# S6E2GMxJ register map
Vendor: Spansion; File version: 2.0
CPU: CM4 r0p1, little endian, MPU, FPU, 4 interrupt priority bits
Registers are 32-bit, read-write, reset 0x0 unless marked. A register's access mark holds for its fields unless they carry their own. Offsets are from the block's base; [hi:lo] are bit positions; {n}, {i} and the like mark numbered series.

## ADC0 — ADC0 Registers
Base 0x40027000
Same registers: ADC1 0x40027100, ADC2 0x40027200
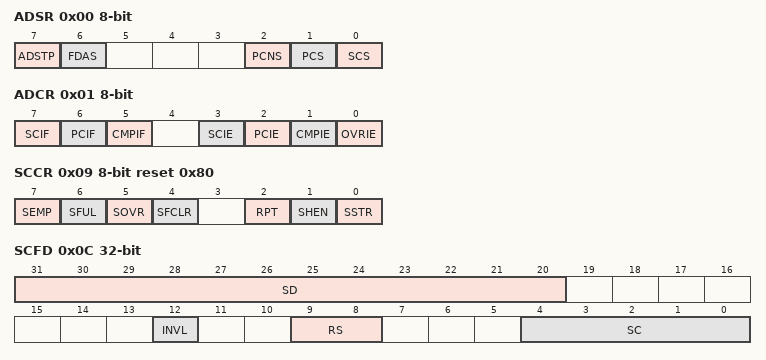
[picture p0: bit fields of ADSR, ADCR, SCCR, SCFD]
0x00 ADSR 8-bit — A/D Status Register
  [7] ADSTP — A/D conversion forced stop bit
  [6] FDAS — FIFO data placement selection bit
  [2] PCNS ro — Priority conversion pending flag
  [1] PCS ro — Priority conversion status flag
  [0] SCS ro — Scan conversion status flag
0x01 ADCR 8-bit — A/D Control Register
  [7] SCIF — Scan conversion interrupt request bit
  [6] PCIF — Priority conversion interrupt request bit
  [5] CMPIF — Conversion result comparison interrupt request bit
  [3] SCIE — Scan conversion interrupt enable bit
  [2] PCIE — Priority conversion interrupt enable bit
  [1] CMPIE — Conversion result comparison interrupt enable bit
  [0] OVRIE — FIFO overrun interrupt enable bit
0x08 SFNS 8-bit — Scan Conversion FIFO Stage Count Setup Register
  [3:0] SFS — Scan conversion FIFO stage count setting bit
0x09 SCCR 8-bit reset 0x80 — Scan Conversion Control Register
  [7] SEMP ro — Scan conversion FIFO empty bit
  [6] SFUL ro — Scan conversion FIFO full bit
  [5] SOVR — Scan conversion overrun flag
  [4] SFCLR — Scan conversion FIFO clear bit
  [2] RPT — Scan conversion repeat bit
  [1] SHEN — Scan conversion timer start enable bit
  [0] SSTR — Scan conversion start bit
0x0C SCFD ro — Scan Conversion FIFO Data Register
  [31:20] SD — Scan conversion result
  [12] INVL — A/D conversion result disable bit
  [9:8] RS — Scan conversion start factor
  [4:0] SC — Conversion input channel bits
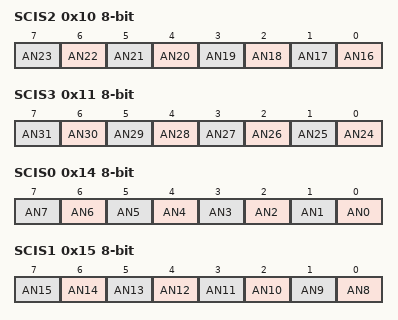
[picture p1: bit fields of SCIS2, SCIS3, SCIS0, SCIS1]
0x10 SCIS2 8-bit — Scan Conversion Input Selection Register 2
  [n-16] AN{n} (n=16..23) — Bit{n-16} of SCIS2
0x11 SCIS3 8-bit — Scan Conversion Input Selection Register 3
  [n-24] AN{n} (n=24..31) — Bit{n-24} of SCIS3
0x14 SCIS0 8-bit — Scan Conversion Input Selection Register 0
  [n] AN{n} (n=0..7) — Bit{n} of SCIS0
0x15 SCIS1 8-bit — Scan Conversion Input Selection Register 1
  [n-8] AN{n} (n=8..15) — Bit{n-8} of SCIS1
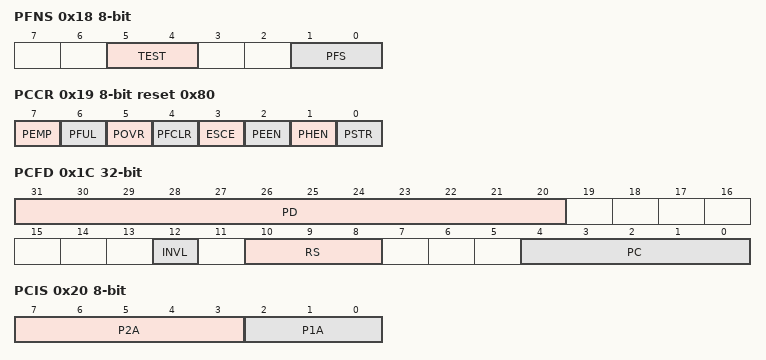
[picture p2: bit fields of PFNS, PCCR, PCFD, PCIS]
0x18 PFNS 8-bit — Priority Conversion FIFO Stage Count Setup Register
  [5:4] TEST ro — Test bits
  [1:0] PFS — Priority conversion FIFO stage count setting bits
0x19 PCCR 8-bit reset 0x80 — Priority Conversion Control Register
  [7] PEMP ro — Priority conversion FIFO empty bit
  [6] PFUL ro — Priority conversion FIFO full bit
  [5] POVR — Priority conversion overrun flag
  [4] PFCLR — Priority conversion FIFO clear bit
  [3] ESCE — External trigger analog input selection bit
  [2] PEEN — Priority conversion external start enable bit
  [1] PHEN — Priority conversion timer start enable bit
  [0] PSTR — Priority conversion start bit
0x1C PCFD ro — Priority Conversion FIFO Data Register
  [31:20] PD — Priority conversion result
  [12] INVL — A/D conversion result disable bit
  [10:8] RS — Scan conversion start factor
  [4:0] PC — Conversion input channel bits
0x20 PCIS 8-bit — Priority Conversion Input Selection Register
  [7:3] P2A — Priority level 2 analog input selection
  [2:0] P1A — Priority level 1 analog input selection
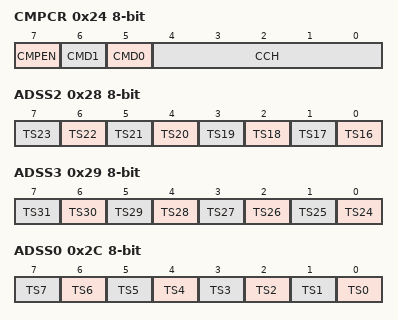
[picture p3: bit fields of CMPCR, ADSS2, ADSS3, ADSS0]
0x24 CMPCR 8-bit — A/D Comparison Control Register
  [7] CMPEN — Conversion result comparison function operation enable bit
  [6] CMD1 — Comparison mode 1
  [5] CMD0 — Comparison mode 0
  [4:0] CCH — Comparison target analog input channel
0x26 CMPD 16-bit — A/D Comparison Value Setup Register
  [15:6] CMAD — A/D conversion result value setting bits
0x28 ADSS2 8-bit — Sampling Time Selection Register 2
  [n-16] TS{n} (n=16..23) — Bit{n-16} of ADSS2
0x29 ADSS3 8-bit — Sampling Time Selection Register 3
  [n-24] TS{n} (n=24..31) — Bit{n-24} of ADSS3
0x2C ADSS0 8-bit — Sampling Time Selection Register 0
  [n] TS{n} (n=0..7) — Bit{n} of ADSS0
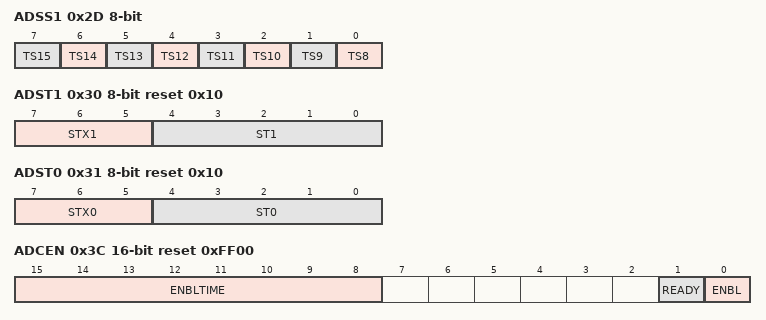
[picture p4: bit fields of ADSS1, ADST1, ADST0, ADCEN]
0x2D ADSS1 8-bit — Sampling Time Selection Register 1
  [n-8] TS{n} (n=8..15) — Bit{n-8} of ADSS1
0x30 ADST1 8-bit reset 0x10 — Sampling Time Setup Register 1
  [7:5] STX1 — Sampling time N times setting bits
  [4:0] ST1 — Sampling time setting bits
0x31 ADST0 8-bit reset 0x10 — Sampling Time Setup Register 0
  [7:5] STX0 — Sampling time N times setting bits
  [4:0] ST0 — Sampling time setting bits
0x34 ADCT 8-bit reset 0x7 — Frequency Division Ratio Setup Register
  [7:0] CT — Frequency division ratio setting bits
0x38 PRTSL 8-bit — Priority Conversion Timer Trigger Selection Register
  [3:0] PRTSL — Priority conversion timer trigger selection bit
0x39 SCTSL 8-bit — Scan Conversion Timer Trigger Selection Register
  [3:0] SCTSL — Scan conversion timer trigger selection bit
0x3C ADCEN 16-bit reset 0xFF00 — A/D Operation Enable Setup Register
  [15:8] ENBLTIME — Operation enable state transition cycle selection bits
  [1] READY ro — A/D operation enable state bit
  [0] ENBL — A/D operation enable bit
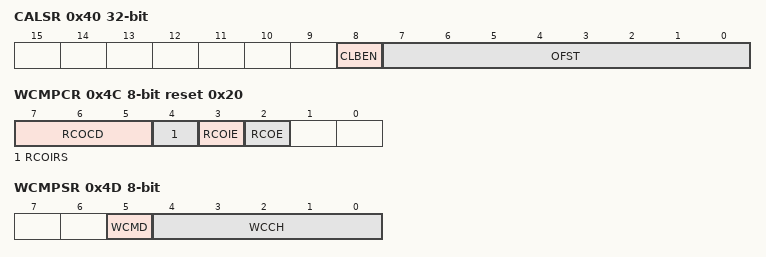
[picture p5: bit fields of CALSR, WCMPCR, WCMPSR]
0x40 CALSR — Calibration Setting Register
  [8] CLBEN — Calibration permission bit
  [7:0] OFST — Offset calibration value setting bits
0x44 WCMRCOT 8-bit — Range Comparison Threshold Excess Flag Register
  [0] RCOOF — Threshold excess flag bit
0x48 WCMRCIF 8-bit — Range Comparison Flag Register
  [0] RCINT — Range comparison interrupt factor flag
0x4C WCMPCR 8-bit reset 0x20 — Range Comparison Control Register
  [7:5] RCOCD — Continuous detection specification count/state indication bits
  [4] RCOIRS — Selection bit of within-range and out-of- range confirmation
  [3] RCOIE — Range comparison interrupt request enable bit
  [2] RCOE — Range comparison execution enable bit
0x4D WCMPSR 8-bit — Range Comparison Channel Select Register
  [5] WCMD — Comparison mode select bit
  [4:0] WCCH — Comparison target analog input channel
0x50 WCMPDL 16-bit — Lower Limit Threshold Setup Register
  [15:6] CMLD — Lower limit threshold bits
0x52 WCMPDH 16-bit — Upper Limit Setup Register
  [15:6] CMHD — Upper limit threshold bits

## Notices in the file
Copyright (C) 2015 Spansion LLC. All Rights Reserved.
This software is owned and published by:
Spansion LLC, 915 DeGuigne Dr. Sunnyvale, CA  94088-3453 ("Spansion").
BY DOWNLOADING, INSTALLING OR USING THIS SOFTWARE, YOU AGREE TO BE BOUND
BY ALL THE TERMS AND CONDITIONS OF THIS AGREEMENT.
This software contains source code for use with Spansion
components. This software is licensed by Spansion to be adapted only
for use in systems utilizing Spansion components. Spansion shall not be
responsible for misuse or illegal use of this software for devices not
supported herein.  Spansion is providing this software "AS IS" and will
not be responsible for issues arising from incorrect user implementation
of the software.
SPANSION MAKES NO WARRANTY, EXPRESS OR IMPLIED, ARISING BY LAW OR OTHERWISE,
REGARDING THE SOFTWARE (INCLUDING ANY ACOOMPANYING WRITTEN MATERIALS),
ITS PERFORMANCE OR SUITABILITY FOR YOUR INTENDED USE, INCLUDING,
WITHOUT LIMITATION, THE IMPLIED WARRANTY OF MERCHANTABILITY, THE IMPLIED
WARRANTY OF FITNESS FOR A PARTICULAR PURPOSE OR USE, AND THE IMPLIED
WARRANTY OF NONINFRINGEMENT.
SPANSION SHALL HAVE NO LIABILITY (WHETHER IN CONTRACT, WARRANTY, TORT,
NEGLIGENCE OR OTHERWISE) FOR ANY DAMAGES WHATSOEVER (INCLUDING, WITHOUT
LIMITATION, DAMAGES FOR LOSS OF BUSINESS PROFITS, BUSINESS INTERRUPTION,
LOSS OF BUSINESS INFORMATION, OR OTHER PECUNIARY LOSS) ARISING FROM USE OR
INABILITY TO USE THE SOFTWARE, INCLUDING, WITHOUT LIMITATION, ANY DIRECT,
INDIRECT, INCIDENTAL, SPECIAL OR CONSEQUENTIAL DAMAGES OR LOSS OF DATA,
SAVINGS OR PROFITS,
EVEN IF SPANSION HAS BEEN ADVISED OF THE POSSIBILITY OF SUCH DAMAGES.
YOU ASSUME ALL RESPONSIBILITIES FOR SELECTION OF THE SOFTWARE TO ACHIEVE YOUR
INTENDED RESULTS, AND FOR THE INSTALLATION OF, USE OF, AND RESULTS OBTAINED
FROM, THE SOFTWARE.
This software may be replicated in part or whole for the licensed use,
with the restriction that this Disclaimer and Copyright notice must be
included with each copy of this software, whether used in part or whole,
at all times.
